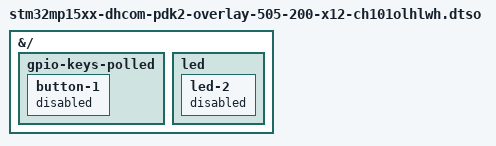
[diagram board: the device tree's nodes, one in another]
// SPDX-License-Identifier: (GPL-2.0+ OR BSD-3-Clause)
/*
 * Copyright (C) 2020 Marek Vasut
 */
/dts-v1/;
/plugin/;

#include "stm32mp15xx-dhcom-overlay-panel-dpi-ch101olhlwh.dtsi"

&{/} {
	gpio-keys-polled {
		/* BUTTON1 GPIO-B conflicts with touchscreen reset */
		button-1 {
			/* Use status as /delete-node/ does not work in DTOs */
			status = "disabled";
		};
	};

	led {
		/* LED7 GPIO-H conflicts with touchscreen IRQ */
		led-2 {
			/* Use status as /delete-node/ does not work in DTOs */
			status = "disabled";
		};
	};
};
